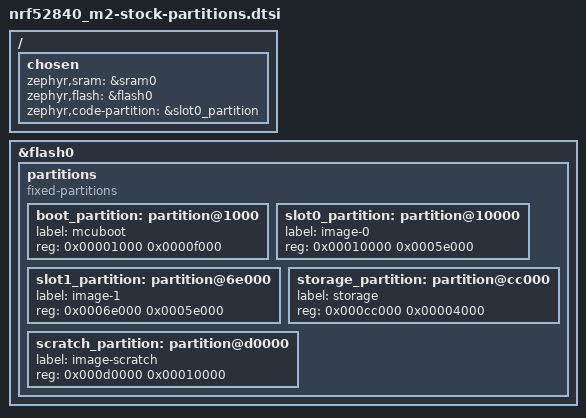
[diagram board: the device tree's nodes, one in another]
/*
 * Flash partition table compatible with the factory Nordic MBR/nRF5 bootloader.
 * SPDX-License-Identifier: Apache-2.0
 */

/ {
	chosen {
		zephyr,sram = &sram0;
		zephyr,flash = &flash0;
		zephyr,code-partition = &slot0_partition;
	};
};

&flash0 {
	partitions {
		compatible = "fixed-partitions";
		#address-cells = <1>;
		#size-cells = <1>;

		boot_partition: partition@1000 {
			label = "mcuboot";
			reg = <0x00001000 0x0000f000>;
		};

		slot0_partition: partition@10000 {
			label = "image-0";
			reg = <0x00010000 0x0005e000>;
		};

		slot1_partition: partition@6e000 {
			label = "image-1";
			reg = <0x0006e000 0x0005e000>;
		};

		storage_partition: partition@cc000 {
			label = "storage";
			reg = <0x000cc000 0x00004000>;
		};

		scratch_partition: partition@d0000 {
			label = "image-scratch";
			reg = <0x000d0000 0x00010000>;
		};
	};
};
